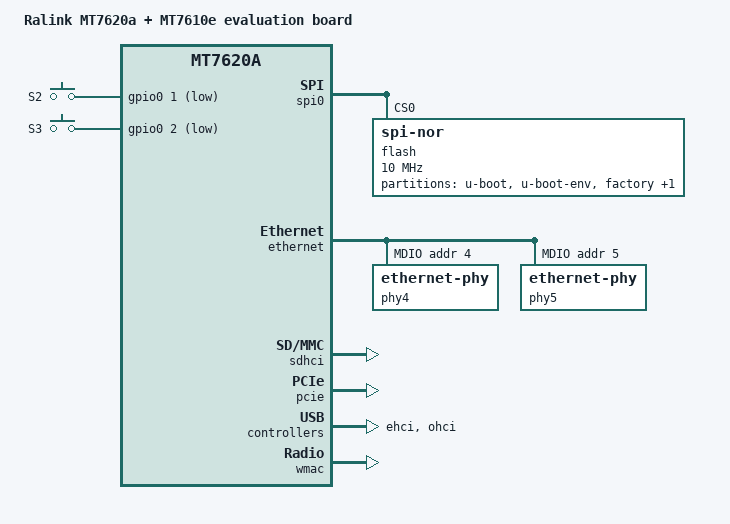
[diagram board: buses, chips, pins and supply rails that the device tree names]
#include "mt7620a.dtsi"

#include <dt-bindings/gpio/gpio.h>
#include <dt-bindings/input/input.h>

/ {
	compatible = "ralink,mt7620a-evb", "ralink,mt7620a-soc";
	model = "Ralink MT7620a + MT7610e evaluation board";

	keys {
		compatible = "gpio-keys";

		s2 {
			label = "S2";
			gpios = <&gpio0 1 GPIO_ACTIVE_LOW>;
			linux,code = <BTN_0>;
		};

		s3 {
			label = "S3";
			gpios = <&gpio0 2 GPIO_ACTIVE_LOW>;
			linux,code = <BTN_1>;
		};
	};
};

&spi0 {
	status = "okay";

	flash@0 {
		compatible = "jedec,spi-nor";
		reg = <0>;
		spi-max-frequency = <10000000>;

		partitions {
			compatible = "fixed-partitions";
			#address-cells = <1>;
			#size-cells = <1>;

			partition@0 {
				label = "u-boot";
				reg = <0x0 0x30000>;
				read-only;
			};

			partition@30000 {
				label = "u-boot-env";
				reg = <0x30000 0x10000>;
				read-only;
			};

			partition@40000 {
				label = "factory";
				reg = <0x40000 0x10000>;
				read-only;
			};

			partition@50000 {
				compatible = "denx,uimage";
				label = "firmware";
				reg = <0x50000 0x7b0000>;
			};
		};
	};
};

&state_default {
	gpio {
		groups = "i2c", "uartf";
		function = "gpio";
	};
};

&ethernet {
	pinctrl-names = "default";
	pinctrl-0 = <&rgmii1_pins &rgmii2_pins &mdio_pins>;

	mediatek,portmap = "llllw";

	port@4 {
		status = "okay";
		phy-mode = "rgmii";
		phy-handle = <&phy4>;
	};

	port@5 {
		status = "okay";
		phy-mode = "rgmii";
		phy-handle = <&phy5>;
	};

	mdio-bus {
		status = "okay";

		phy4: ethernet-phy@4 {
			reg = <4>;
			phy-mode = "rgmii";
		};

		phy5: ethernet-phy@5 {
			reg = <5>;
			phy-mode = "rgmii";
		};
	};
};

&gsw {
	mediatek,port4-gmac;
	mediatek,ephy-base = /bits/ 8 <8>;
};

&sdhci {
	status = "okay";
};

&pcie {
	status = "okay";
};

&ehci {
	status = "okay";
};

&ohci {
	status = "okay";
};

&wmac {
	ralink,eeprom-data = <0x20760501 0xb4750eed 0x1f0cffff 0xffffffff 0xffffffff 0xffffffff 0xffffffff 0xffffffff
				0xffffffff 0xffffffff 0xb4750eed 0x1f0eb475 0x00ed1f0f 0x220c0000 0xffff5001 0x5577a8aa
				0x8c88ffff 0x0a000000 0x00000000 0x0000ffff 0xffff0c0b 0x0b0b0a0a 0x0a0a0a0a 0x0a0a0a0a
				0x0f0e0e0e 0x0d0d0d0d 0x0d0d0d0d 0x0e0e80ff 0xffff80ff 0xffff0000 0xffffffff 0xffffffff
				0xffffffff 0xffffffff 0xffffffff 0xffffffff 0xffffffff 0xffffffff 0xffffffff 0xffffffff
				0xffffffff 0xffffffff 0xffffffff 0xffffffff 0xffffffff 0xffffffff 0xffffffff 0xffffffff
				0xffffffff 0xffffffff 0xffffffff 0xffffffff 0x20ffffff 0xffffffff 0xffffffff 0xffff0606
				0x08080400 0x07070400 0x08080400 0x07070400 0xffffffff 0xffffffff 0xffffffff 0xffffffff
				0xffffffff 0xffffffff 0xffffffff 0xffffffff 0xffffffff 0xffffffff 0xffffffff 0xffffffff
				0xffffffff 0xffffffff 0xffffffff 0xffffffff 0xffffffff 0xffffffff 0xffffffff 0xffffffff
				0xffffffff 0xffffffff 0xffffffff 0xffffffff 0xffffffff 0xffffffff 0xffffffff 0xffffffff
				0xffffffff 0xffffffff 0xffffffff 0xffffffff 0xffffffff 0xffffffff 0xffffffff 0xffffffff
				0xffffffff 0xffffffff 0xffffffff 0xffffffff 0xffffffff 0xffffffff 0xffffffff 0xffffffff
				0xffffffff 0xffffffff 0xffffffff 0xffffffff 0xffffffff 0xffffffff 0xffffffff 0xffffffff
				0xffffffff 0xffffffff 0xffffffff 0xffffffff 0xffffffff 0xffffffff 0xffffffff 0xffffffff
				0xffffffff 0xffffffff 0xffffffff 0xffffffff 0xffffffff 0xffffffff 0xffffffff 0xffffffff>;
};
